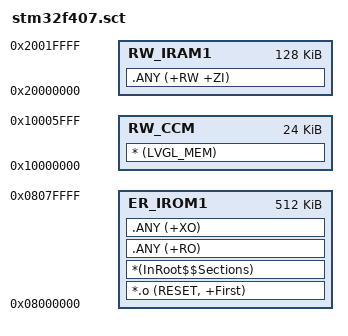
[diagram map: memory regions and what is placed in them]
; *************************************************************
; One load region in Flash. Do not add a load region at 0x10000000:
; the ST-Link flash loader can only program 0x08000000.
; LVGL_MEM is zero-initialized in CCM at startup. DMA buffers stay in SRAM.
; *************************************************************

LR_IROM1 0x08000000 0x00080000  {
  ER_IROM1 0x08000000 0x00080000  {
   *.o (RESET, +First)
   *(InRoot$$Sections)
   .ANY (+RO)
   .ANY (+XO)
  }
  RW_CCM 0x10000000 0x00006000  {
   * (LVGL_MEM)
  }
  RW_IRAM1 0x20000000 0x00020000  {
   .ANY (+RW +ZI)
  }
}
